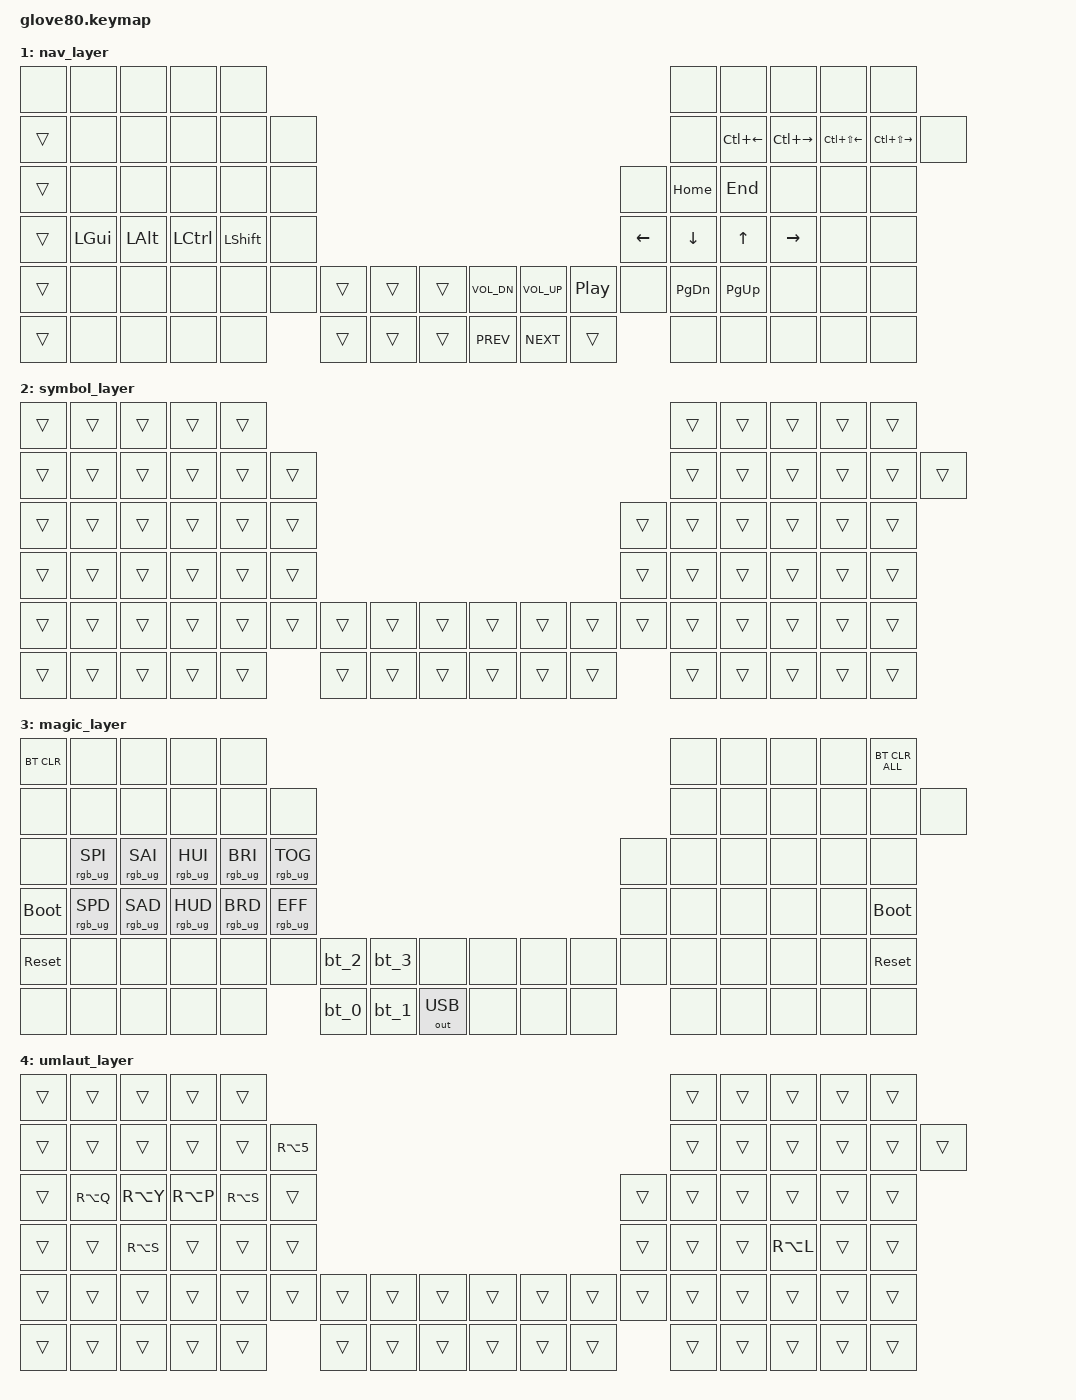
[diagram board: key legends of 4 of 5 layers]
/*
 * Copyright (c) 2020 The ZMK Contributors
 *
 * SPDX-License-Identifier: MIT
 */

#include <behaviors.dtsi>
#include <dt-bindings/zmk/keys.h>
#include <dt-bindings/zmk/bt.h>
#include <dt-bindings/zmk/ext_power.h>
#include <dt-bindings/zmk/outputs.h>
#include <dt-bindings/zmk/rgb.h>

#include "glove80KeyPositionIndices.h"

#include "shared/shared.h"



/ {
    behaviors {
        // For the "layer" key, it'd nice to be able to use it as either a shift or a toggle.
        // Configure it as a tap dance, so the first tap (or hold) is a &mo and the second tap is a &to
        layer_td: tap_dance_0 {
            compatible = "zmk,behavior-tap-dance";
            label = "LAYER_TAP_DANCE";
            #binding-cells = <0>;
            tapping-term-ms = <200>;
            bindings = <&mo NAV>, <&to NAV>;
        };

        magic: magic_hold_tap {
            compatible = "zmk,behavior-hold-tap";
            label = "MAGIC_HOLD_TAP";
            #binding-cells = <2>;
            flavor = "tap-preferred";
            tapping-term-ms = <200>;
            bindings = <&mo>, <&rgb_ug_status_macro>;
        };

        HRM_BEHAVIORS

        NAV_LAYER_STICKY_SHIFT_BEHAVIOR

        HOME_ROW_LAYER_TAP_BEHAVIOR
    };

    macros {
        rgb_ug_status_macro: rgb_ug_status_macro_0 {
            label = "RGB_UG_STATUS";
            compatible = "zmk,behavior-macro";
            #binding-cells = <0>;
            bindings
                = <&rgb_ug RGB_STATUS>;
        };

        bt_0: bt_profile_macro_0 {
            label = "BT_0";
            compatible = "zmk,behavior-macro";
            #binding-cells = <0>;
            bindings
                = <&out OUT_BLE>,
                  <&bt BT_SEL 0>;
        };

        bt_1: bt_profile_macro_1 {
            label = "BT_1";
            compatible = "zmk,behavior-macro";
            #binding-cells = <0>;
            bindings
                = <&out OUT_BLE>,
                  <&bt BT_SEL 1>;
        };

        bt_2: bt_profile_macro_2 {
            label = "BT_2";
            compatible = "zmk,behavior-macro";
            #binding-cells = <0>;
            bindings
                = <&out OUT_BLE>,
                  <&bt BT_SEL 2>;
        };

        bt_3: bt_profile_macro_3 {
            label = "BT_3";
            compatible = "zmk,behavior-macro";
            #binding-cells = <0>;
            bindings
                = <&out OUT_BLE>,
                  <&bt BT_SEL 3>;
        };
    };

    keymap {
        compatible = "zmk,keymap";

        default_layer {
            // ---------------------------------------------------------------------------------------------------------------------------------
            // |  F1   |  F2 |  F3 |  F4  |  F5  |                                                               |  F6   |  F7   |  F8  |   F9  |  F10 |
            // |  =    |  1  |  2  |  3   |  4   |  5   |                                                 |  6   |   7   |   8   |  9   |   0   |   -  |
            // |  TAB  |  Q  |  W  |  E   |  R   |  T   |                                                 |  Y   |   U   |   I   |  O   |   P   |   \  |
            // |  ESC  |  A  |  S  |  D   |  F   |  G   |                                                 |  H   |   J   |   K   |  L   |   ;   |   '  |
            // |   `   |  Z  |  X  |  C   |  V   |  B   | LSHFT | LCTRL | LOWER | | LGUI  | RCTRL | RSHFT |  N   |   M   |   ,   |  .   |   /   | PGUP |
            // | MAGIC | HOME| END | LEFT | RIGHT|      | BSPC  | DEL   | LALT  | | RALT  | RET   | SPACE |      |  UP   | DOWN  |  [   |   ]   | PGDN |

            // TODO make umlaut lt use hrm config, but with momentary layer instead of kp of course

            bindings = <
            &kp GRAVE      &kp F2   &kp F3      &kp F4      &kp F5                                                                                                         &kp F8  &kp F9      &kp F10      &kp F11      &kp F12
            &kp EQUAL      &kp N1   &kp N2      &kp N3      &kp N4      &kp N5                                                                                     &kp N6  &kp N7  &kp N8      &kp N9      &kp N0      &kp MINUS
            &kp TAB        &kp Q    &kp W       &kp E       &kp R       &kp T                                                                                      &kp Y   &kp U   &kp I       &kp O       &kp P       &kp BSLH

            DEFAULT_HOME_ROW_MAP

            &kp LSHIFT     &kp Z    &kp X       &kp C       &kp V       &kp B   &kp BSPC                    &kp DEL     &layer_td  &kp LGUI   &kp RCTRL &kp SPACE  &kp N   &kp M   &kp COMMA   &kp DOT     &kp FSLH    &kp PG_UP
            &magic MAGIC 0 &none    &kp LGUI    &kp LALT    &none               &nav_sticky_shift NAV LSHFT &kp DEL     &kp LALT   &caps_word &mo MAGIC &kp RET            &none   &kp LBKT    &kp RBKT    &none       &kp PG_DN
            >;
        };

        nav_layer {
            bindings = <
            &none             &none         &none      &none      &none                                                                                                            &none        &none     &none      &none    &none    
            &trans            &none         &none      &none      &none         &none                                                                                 &none        &kp LC(LEFT) &kp LC(RIGHT) &kp LC(LS(LEFT)) &kp LC(LS(RIGHT)) &none
            &trans            &none         &none      &none      &none         &none                                                                                 &none        &kp HOME     &kp END   &none      &none    &none
            &trans            &kp LGUI      &kp LALT   &kp LCTRL  &kp LSHIFT    &none                                                                                 &kp LEFT     &kp DOWN     &kp UP    &kp RIGHT  &none    &none
            &trans            &none         &none      &none      &none         &none       &trans      &trans      &trans      &kp C_VOL_DN &kp C_VOL_UP &kp C_PP    &none        &kp PG_DN    &kp PG_UP &none      &none    &none
            &trans            &none         &none      &none      &none                     &trans      &trans      &trans      &kp C_PREV   &kp C_NEXT   &trans                   &none        &none     &none      &none    &none
            >;
        };

        symbol_layer {
            bindings = <
            &trans   &trans   &trans   &trans   &trans                                                                              &trans   &trans   &trans   &trans   &trans
            &trans   &trans   &trans   &trans   &trans   &trans                                                            &trans   &trans   &trans   &trans   &trans   &trans
            &trans   &trans   &trans   &trans   &trans   &trans                                                            &trans   &trans   &trans   &trans   &trans   &trans
            &trans   &trans   &trans   &trans   &trans   &trans                                                            &trans   &trans   &trans   &trans   &trans   &trans
            &trans   &trans   &trans   &trans   &trans   &trans   &trans   &trans   &trans      &trans   &trans   &trans   &trans   &trans   &trans   &trans   &trans   &trans
            &trans   &trans   &trans   &trans   &trans            &trans   &trans   &trans      &trans   &trans   &trans            &trans   &trans   &trans   &trans   &trans
            >;
        };


        magic_layer {
            bindings = <
            &bt BT_CLR        &none               &none           &none           &none                                                                                                           &none      &none      &none      &none      &bt BT_CLR_ALL
            &none             &none               &none           &none           &none           &none                                                                                &none      &none      &none      &none      &none      &none
            &none             &rgb_ug RGB_SPI     &rgb_ug RGB_SAI &rgb_ug RGB_HUI &rgb_ug RGB_BRI &rgb_ug RGB_TOG                                                                      &none      &none      &none      &none      &none      &none
            &bootloader       &rgb_ug RGB_SPD     &rgb_ug RGB_SAD &rgb_ug RGB_HUD &rgb_ug RGB_BRD &rgb_ug RGB_EFF                                                                      &none      &none      &none      &none      &none      &bootloader
            &sys_reset        &none               &none           &none           &none           &none           &bt_2     &bt_3     &none            &none     &none     &none       &none      &none      &none      &none      &none      &sys_reset
            &none             &none               &none           &none           &none                           &bt_0     &bt_1     &out OUT_USB     &none     &none     &none                  &none      &none      &none      &none      &none
            >;
        };

        umlaut_layer {
            bindings = <
            &trans   &trans   &trans   &trans   &trans                                                                              &trans   &trans   &trans   &trans   &trans
            &trans   &trans   &trans   &trans   &trans   &kp RA(N5)                                                        &trans   &trans   &trans   &trans   &trans   &trans
            &trans   &kp RA(Q)&kp RA(Y)&kp RA(P)&kp RA(S)&trans                                                            &trans   &trans   &trans   &trans   &trans   &trans
            &trans   &trans   &kp RA(S)&trans   &trans   &trans                                                            &trans   &trans   &trans   &kp RA(L)&trans   &trans
            &trans   &trans   &trans   &trans   &trans   &trans   &trans   &trans   &trans      &trans   &trans   &trans   &trans   &trans   &trans   &trans   &trans   &trans
            &trans   &trans   &trans   &trans   &trans            &trans   &trans   &trans      &trans   &trans   &trans            &trans   &trans   &trans   &trans   &trans
            >;
        };
    };
};
